VERSION ""

NS_ :

BS_:

BU_: XXX

BO_ 76 RCMStatusMessage2_FD1: 8 XXX
 SG_ FirstRowBuckleDriver : 15|2@0+ (1,0) [0|3] "" XXX

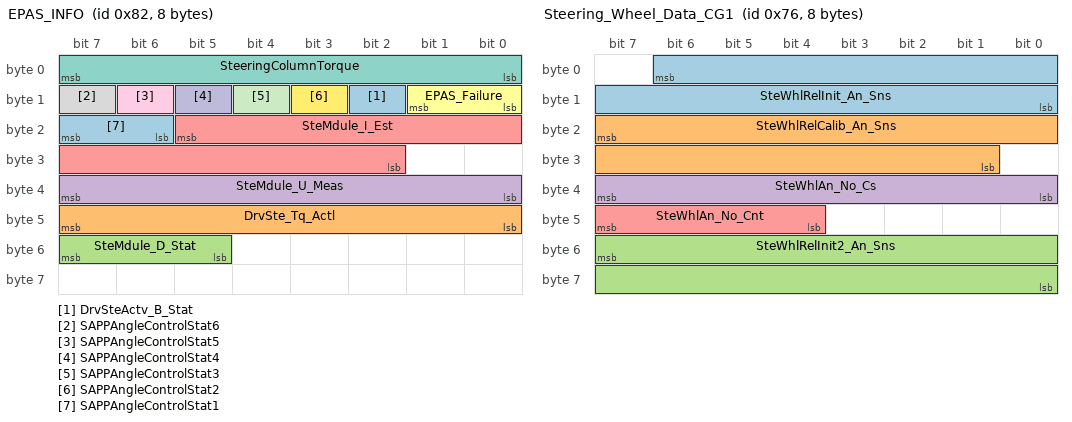
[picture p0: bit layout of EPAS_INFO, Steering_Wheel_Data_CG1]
BO_ 130 EPAS_INFO: 8 XXX
 SG_ DrvSteActv_B_Stat : 10|1@0+ (1,0) [0|1] ""  XXX
 SG_ DrvSte_Tq_Actl : 47|8@0+ (0.0625,-8) [-8|7.8125] "Nm"  XXX
 SG_ SteMdule_D_Stat : 55|3@0+ (1,0) [0|7] "" XXX
 SG_ SteMdule_U_Meas : 39|8@0+ (0.05,6) [6|18.7] "Volts"  XXX
 SG_ SteMdule_I_Est : 21|12@0+ (0.05,-64) [-64|140.7] "Amps"  XXX
 SG_ EPAS_Failure : 9|2@0+ (1,0) [0|3] "" XXX
 SG_ SteeringColumnTorque : 7|8@0+ (0.0625,-8) [-8|7.8125] "Nm"  XXX
 SG_ SAPPAngleControlStat6 : 15|1@0+ (1,0) [0|1] "" XXX
 SG_ SAPPAngleControlStat5 : 14|1@0+ (1,0) [0|1] "" XXX
 SG_ SAPPAngleControlStat4 : 13|1@0+ (1,0) [0|1] "" XXX
 SG_ SAPPAngleControlStat3 : 12|1@0+ (1,0) [0|1] "" XXX
 SG_ SAPPAngleControlStat2 : 11|1@0+ (1,0) [0|1] "" XXX
 SG_ SAPPAngleControlStat1 : 23|2@0+ (1,0) [0|3] "" XXX

BO_ 118 Steering_Wheel_Data_CG1: 8 XXX
 SG_ SteWhlRelInit_An_Sns : 6|15@0+ (0.1,-1600.0) [0|0] "deg" XXX
 SG_ SteWhlRelCalib_An_Sns : 23|15@0+ (0.1,-1600.0) [0|0] "deg" XXX
 SG_ SteWhlRelInit2_An_Sns : 55|16@0+ (0.1,-3200.0) [0|0] "deg" XXX
 SG_ SteWhlAn_No_Cs : 39|8@0+ (1,0) [0|0] "" XXX
 SG_ SteWhlAn_No_Cnt : 47|4@0+ (1,0) [0|0] "Counts" XXX

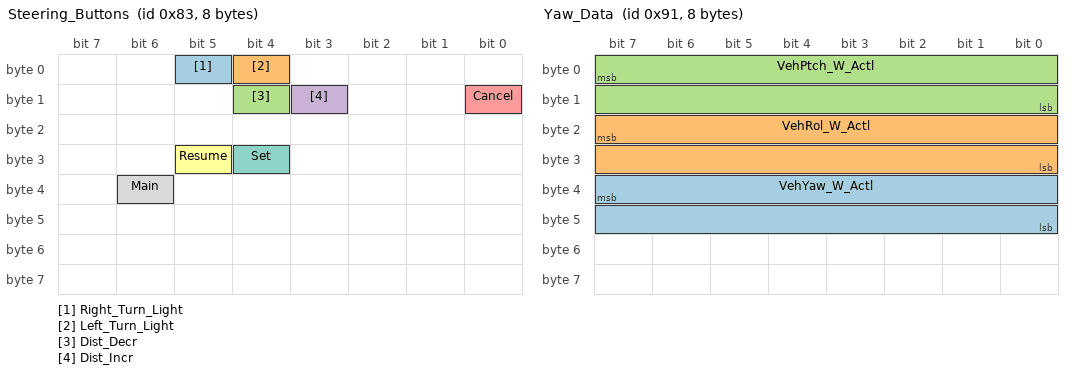
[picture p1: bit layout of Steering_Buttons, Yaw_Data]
BO_ 131 Steering_Buttons: 8 XXX
 SG_ Right_Turn_Light : 5|1@0+ (1,0) [0|0] "" XXX
 SG_ Left_Turn_Light : 4|1@0+ (1,0) [0|0] "" XXX
 SG_ Dist_Decr : 12|1@0+ (1,0) [0|0] "" XXX
 SG_ Dist_Incr : 11|1@0+ (1,0) [0|0] "" XXX
 SG_ Cancel : 8|1@0+ (1,0) [0|0] "" XXX
 SG_ Resume : 29|1@0+ (1,0) [0|0] "" XXX
 SG_ Set : 28|1@0+ (1,0) [0|0] "" XXX
 SG_ Main : 38|1@0+ (1,0) [0|0] "" XXX

BO_ 145 Yaw_Data: 8 XXX
 SG_ VehYaw_W_Actl : 39|16@0+ (0.0002,-6.5) [0|0] "rad/s" XXX
 SG_ VehRol_W_Actl : 23|16@0+ (0.0002,-6.5) [0|0] "rad/s" XXX
 SG_ VehPtch_W_Actl : 7|16@0+ (0.0002,-6.5) [0|0] "rad/s" XXX

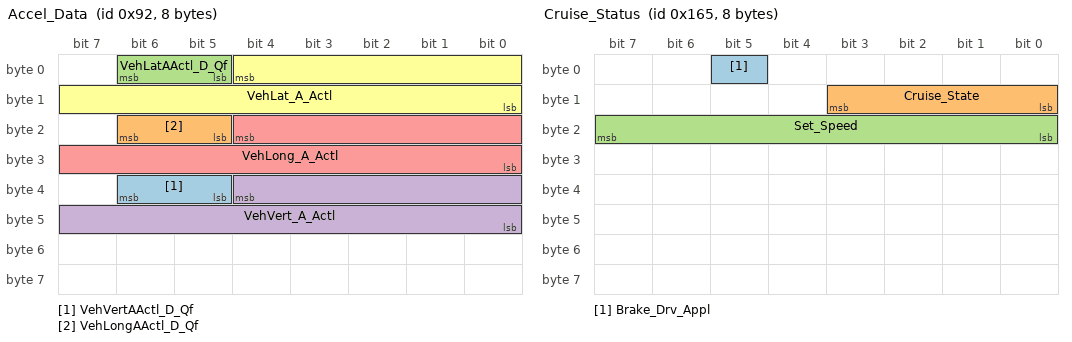
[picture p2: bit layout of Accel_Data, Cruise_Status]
BO_ 146 Accel_Data: 8 XXX
 SG_ VehVertAActl_D_Qf : 38|2@0+ (1,0) [0|0] "" XXX
 SG_ VehLongAActl_D_Qf : 22|2@0+ (1,0) [0|0] "" XXX
 SG_ VehLatAActl_D_Qf : 6|2@0+ (1,0) [0|0] "" XXX
 SG_ VehVert_A_Actl : 36|13@0+ (0.01,-40.0) [0|0] "m/s^2" XXX
 SG_ VehLong_A_Actl : 20|13@0+ (0.01,-40.0) [0|0] "m/s^2" XXX
 SG_ VehLat_A_Actl : 4|13@0+ (0.01,-40.0) [0|0] "m/s^2" XXX

BO_ 357 Cruise_Status: 8 XXX
 SG_ Brake_Drv_Appl : 5|1@0+ (1,0) [0|0] "" XXX
 SG_ Cruise_State : 11|4@0+ (1,0) [0|0] "" XXX
 SG_ Set_Speed : 23|8@0+ (1,0) [0|0] "" XXX

BO_ 516 EngineData_14: 8 XXX
 SG_ ApedPosScal_Pc_Actl : 1|10@0+ (0.1,0) [0|0] "%" XXX

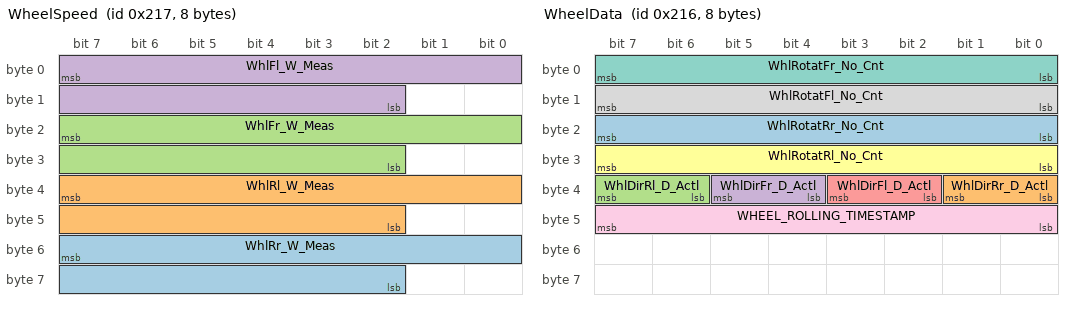
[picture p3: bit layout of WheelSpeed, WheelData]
BO_ 535 WheelSpeed: 8 XXX
 SG_ WhlRr_W_Meas : 55|14@0+ (0.04,0) [0|0] "rad/s" XXX
 SG_ WhlRl_W_Meas : 39|14@0+ (0.04,0) [0|0] "rad/s" XXX
 SG_ WhlFr_W_Meas : 23|14@0+ (0.04,0) [0|0] "rad/s" XXX
 SG_ WhlFl_W_Meas : 7|14@0+ (0.04,0) [0|0] "rad/s" XXX

BO_ 534 WheelData: 8 XXX
 SG_ WhlRotatRr_No_Cnt : 23|8@0+ (1,0) [0|0] "" XXX
 SG_ WhlDirRr_D_Actl : 33|2@0+ (1,0) [0|0] "" XXX
 SG_ WhlDirRl_D_Actl : 39|2@0+ (1,0) [0|0] "" XXX
 SG_ WhlDirFr_D_Actl : 37|2@0+ (1,0) [0|0] "" XXX
 SG_ WhlDirFl_D_Actl : 35|2@0+ (1,0) [0|0] "" XXX
 SG_ WhlRotatRl_No_Cnt : 31|8@0+ (1,0) [0|0] "" XXX
 SG_ WhlRotatFr_No_Cnt : 7|8@0+ (1,0) [0|0] "" XXX
 SG_ WhlRotatFl_No_Cnt : 15|8@0+ (1,0) [0|0] "" XXX
 SG_ WHEEL_ROLLING_TIMESTAMP : 47|8@0+ (1,0) [0|0] "" XXX

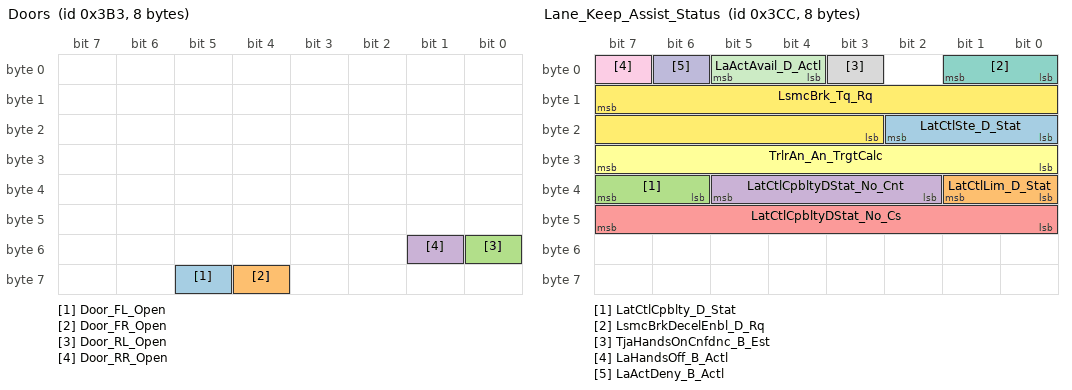
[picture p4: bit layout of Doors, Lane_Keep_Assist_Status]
BO_ 947 Doors: 8 XXX
 SG_ Door_FL_Open : 61|1@0+ (1,0) [0|0] "" XXX
 SG_ Door_FR_Open : 60|1@0+ (1,0) [0|0] "" XXX
 SG_ Door_RL_Open : 48|1@0+ (1,0) [0|0] "" XXX
 SG_ Door_RR_Open : 49|1@0+ (1,0) [0|0] "" XXX

BO_ 963 BCM_to_HS_Body: 8 XXX
 SG_ Brake_Lights : 8|1@0+ (1,0) [0|0] "" XXX

BO_ 970 Lane_Keep_Assist_Control: 8 XXX
 SG_ Lkas_Action : 7|3@0+ (1,0) [0|7] ""  XXX
 SG_ Lkas_Alert : 3|4@0+ (1,0) [0|15] "" XXX
 SG_ Lane_Curvature : 15|12@0+ (5E-006,-0.01024) [-0.01024|0.01023] "1/m"  XXX
 SG_ Steer_Angle_Req : 19|12@0+ (0.05,-102.4) [-102.4|102.3] "deg"  XXX
 SG_ LkaDrvOvrrd_D_Rq : 38|2@0+ (1,0) [0|3] "" XXX
 SG_ LdwActvStats_D_Req : 4|3@0+ (1,0) [0|7] "" XXX
 SG_ LdwActvIntns_D_Req : 1|2@0+ (1,0) [0|3] "" XXX
 SG_ LaRampType_B_Req : 39|1@0+ (1,0) [0|1] "" XXX

BO_ 972 Lane_Keep_Assist_Status: 8 XXX
 SG_ LatCtlSte_D_Stat : 18|3@0+ (1,0) [0|7] ""  XXX
 SG_ LatCtlLim_D_Stat : 33|2@0+ (1,0) [0|3] ""  XXX
 SG_ LatCtlCpblty_D_Stat : 39|2@0+ (1,0) [0|3] ""  XXX
 SG_ LatCtlCpbltyDStat_No_Cnt : 37|4@0+ (1,0) [0|15] ""  XXX
 SG_ LatCtlCpbltyDStat_No_Cs : 47|8@0+ (1,0) [0|255] ""  XXX
 SG_ TrlrAn_An_TrgtCalc : 31|8@0+ (1,-128) [-128|127] ""  XXX
 SG_ LsmcBrkDecelEnbl_D_Rq : 1|2@0+ (1,0) [0|3] ""  XXX
 SG_ TjaHandsOnCnfdnc_B_Est : 3|1@0+ (1,0) [0|1] ""  XXX
 SG_ LaHandsOff_B_Actl : 7|1@0+ (1,0) [0|1] ""  XXX
 SG_ LaActDeny_B_Actl : 6|1@0+ (1,0) [0|1] ""  XXX,XXX
 SG_ LaActAvail_D_Actl : 5|2@0+ (1,0) [0|3] ""  XXX,XXX
 SG_ LsmcBrk_Tq_Rq : 15|13@0+ (4,0) [0|32764] "Nm"  XXX

BO_ 984 Lane_Keep_Assist_Ui: 8 XXX
 SG_ FeatConfigIpmaActl : 7|16@0+ (1,0) [0|65535] ""  XXX
 SG_ FeatNoIpmaActl : 23|16@0+ (1,0) [0|65535] ""  XXX
 SG_ PersIndexIpma_D_Actl : 39|3@0+ (1,0) [0|7] ""  XXX
 SG_ AhbcRampingV_D_Rq : 57|2@0+ (1,0) [0|3] ""  XXX
 SG_ Lines_Hud : 55|5@0+ (1,0) [0|31] ""  XXX
 SG_ LaDenyStats_B_Dsply : 32|1@0+ (1,0) [0|1] ""  XXX
 SG_ Hands_Warning_W_Chime : 50|2@0+ (1,0) [0|3] ""  XXX
 SG_ CamraDefog_B_Req : 36|1@0+ (1,0) [0|1] ""  XXX
 SG_ CamraStats_D_Dsply : 35|2@0+ (1,0) [0|3] ""  XXX
 SG_ DasAlrtLvl_D_Dsply : 42|3@0+ (1,0) [0|7] ""  XXX
 SG_ DasStats_D_Dsply : 47|2@0+ (1,0) [0|3] ""  XXX
 SG_ DasWarn_D_Dsply : 44|2@0+ (1,0) [0|3] ""  XXX
 SG_ AhbHiBeam_D_Rq : 59|2@0+ (1,0) [0|3] ""  XXX
 SG_ Hands_Warning : 49|1@0+ (1,0) [0|1] ""  XXX
 SG_ Set_Me_X30 : 63|8@0+ (1,0) [0|255] ""  XXX

CM_ SG_ 970 Lkas_Action "only vals 4, 5, 8, 9 seem to work. 4 and 5 are a bit smoother" ;

VAL_ 76 FirstRowBuckleDriver 3 "Unknown" 2 "Unbelted" 1 "Belted" 0 "Faulty" ;
VAL_ 130 DrvSte_Tq_Actl 255 "Invalid" 254 "Unknown" ;
VAL_ 130 SteeringColumnTorque 255 "Invalid" 254 "Unknown" ;
VAL_ 972 LatCtlSte_D_Stat 7 "NotUsed3" 6 "NotUsed2" 5 "NotUsed1" 4 "Denied" 3 "RampOut" 2 "ContLatControlInProgress" 1 "Available" 0 "Unavailable" ;
VAL_ 972 LatCtlLim_D_Stat 3 "LimitWithDriverActive" 2 "LimitReached" 1 "LimitClose" 0 "LimitNotReached" ;
VAL_ 984 AhbcRampingV_D_Rq 3 "Slow" 2 "Medium" 1 "Fast" 0 "Immediately" ;
VAL_ 984 CamraDefog_B_Req 1 "On" 0 "Off" ;
VAL_ 984 AhbHiBeam_D_Rq 3 "NotUsed" 2 "HighBeamRecommended" 1 "LowBeamRecommended" 0 "DeactivatedUnavailable" ; "LCA_LKA_LDW_Suppress" ;
VAL_ 357 Cruise_State 4 "active" 3 "standby" 0 "off" ;
VAL_ 970 Lkas_Action 15 "off" 14 "alert_only_active" 9 "aid_active_turn_left" 8 "aid_and_alert_turn_left" 5 "aid_active_turn_right" 4 "aid_and_alert_turn_right" 1 "aid_only_active" 0 "alert_and_aid_active";
VAL_ 970 Lkas_Alert 15 "no_alert" 3 "high_intensity" 2 "mid_intensity" 1 "low_intensity" ;
VAL_ 972 LaActAvail_D_Actl 3 "available" 2 "tbd" 1 "not_available" 0 "fault" ;
VAL_ 984 Lines_Hud 15 "none" 11 "grey_yellow" 8 "green_red" 7 "yellow_grey" 6 "grey_grey" 4 "red_green" 3 "green_green" ;
